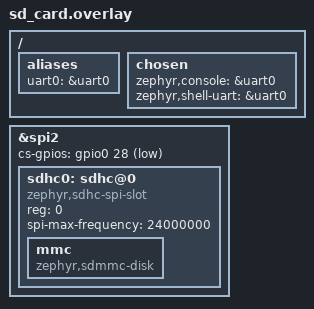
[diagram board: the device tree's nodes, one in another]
/*
https://files.seeedstudio.com/wiki/XIAO-BLE/Seeed-Studio-XIAO-nRF52840-Sense-v1.1.pdf

SD card connected to
MOSI P1.15 (MOSI)
MISO P1.14 (MISO)
CLK P1.13 (SCK)
CS, P0.02 (A0)

Battery VDiv connected to
P0.28 (A2)

UART connected to
P1.11 (TX)
P1.12 (RX)
*/

/ {
    aliases {
        uart0 = &uart0;
    };

    chosen {
        zephyr,console = &uart0;
        zephyr,shell-uart = &uart0;
        // zephyr,uart-mcumgr = &uart0;
    };
};

&spi2 {
    status = "okay";
    // cs-gpios = <&gpio0 2 GPIO_ACTIVE_LOW>; // Adafruit microSD Card BFF Add-On for QT Py and Xiao
    cs-gpios = <&gpio0 28 GPIO_ACTIVE_LOW>; // Seeeduino XIAO Expansion Board

    sdhc0: sdhc@0 {
        compatible = "zephyr,sdhc-spi-slot";
        reg = <0>;
        status = "okay";
        mmc {
            compatible = "zephyr,sdmmc-disk";
            status = "okay";
        };
        spi-max-frequency = <24000000>;
    };
};
